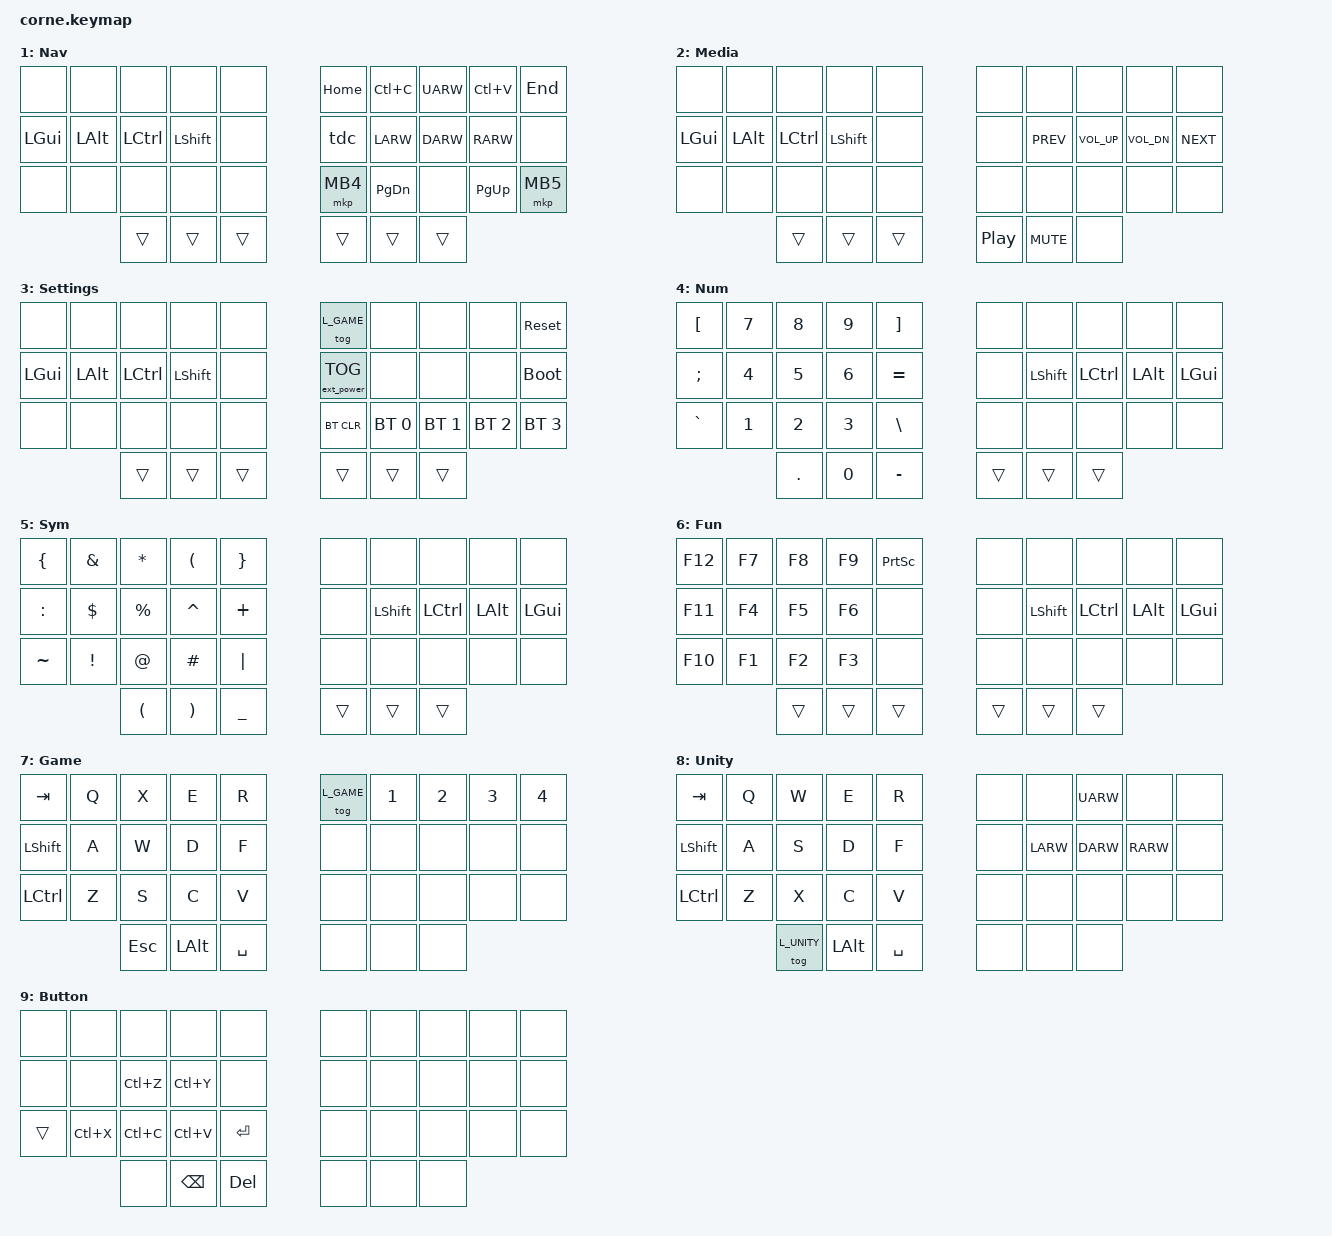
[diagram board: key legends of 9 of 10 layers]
// Copyright (c) 2022 The ZMK Contributors
// SPDX-License-Identifier: MIT

#include <behaviors.dtsi>
#include <dt-bindings/zmk/keys.h>
#include <dt-bindings/zmk/bt.h>
#include <dt-bindings/zmk/mouse.h>
#include <dt-bindings/zmk/ext_power.h>

// Layers
#define L_BASE      0
#define L_NAV       1
#define L_MEDIA     2
#define L_SETTINGS  3
#define L_NUM       4
#define L_SYM       5
#define L_FUN       6
#define L_GAME      7
#define L_UNITY     8
#define L_BUTTON    9

// Home rows
#define HRML(k1,k2,k3,k4) &pmt LGUI  k1  &mt LALT  k2   &mt LCTRL k3   &mt LSHFT k4
#define HRMR(k1,k2,k3,k4) &mt RSHFT k1   &mt RCTRL k2   &mt LALT  k3   &pmt RGUI k4

// Layer-taps
#define LT_MEDIA    &lt  L_MEDIA    TAB
#define LT_NAV      &lt  L_NAV      SPACE
#define LT_NUM      &lt  L_NUM      BSPC
#define LT_SYM      &lt  L_SYM      ENTER
#define LT_FUN      &lt  L_FUN      DEL
#define LT_BUT      &plt L_BUTTON   Z

// Layer-toggles
#define TOG_UNI     &tog L_UNITY
#define TOG_GAME    &tog L_GAME

// Other
#define POW_TOG &ext_power EP_TOG

&mt {
    flavor = "tap-preferred";
    tapping-term-ms = <200>;
    require-prior-idle-ms = <100>;
};

&lt {
    tapping-term-ms = <200>;
    quick-tap-ms = <150>;
};

/ {
    chosen {
      zmk,matrix_transform = &five_column_transform;
    };

    behaviors {
        pmt: pinkie_mod_tap {
            compatible = "zmk,behavior-hold-tap";
            #binding-cells = <2>;
            flavor = "tap-preferred";
            tapping-term-ms = <300>;
            require-prior-idle-ms = <150>;
            bindings = <&kp>, <&kp>;
        };

        plt: pinkie_layer_tap {
            compatible = "zmk,behavior-hold-tap";
            #binding-cells = <2>;
            flavor = "tap-preferred";
            tapping-term-ms = <250>;
            require-prior-idle-ms = <150>;
            bindings = <&mo>, <&kp>;
        };

        tdc: tap_dance_caps {
            compatible = "zmk,behavior-tap-dance";
            #binding-cells = <0>;
            tapping-term-ms = <200>;
            bindings = <&caps_word>, <&kp CAPS>;
        };
    };

    combos {
        compatible = "zmk,combos";

        combo_esc {
            timeout-ms = <50>;
            require-prior-idle-ms = <100>;
            key-positions = <0 1>;
            bindings = <&kp ESC>;
        };
    };

    conditional_layers {
        compatible = "zmk,conditional-layers";

        layer_tri_settings {
            if-layers = <L_NAV L_MEDIA>;
            then-layer = <L_SETTINGS>;
        };
    };

    keymap {
        compatible = "zmk,keymap";
        layer_base {
            display-name = "Base";
            bindings = <
        //╭──────────┬──────────┬──────────┬──────────┬──────────╮   ╭──────────┬──────────┬──────────┬──────────┬──────────╮
            &kp Q      &kp W      &kp E      &kp R      &kp T          &kp Y      &kp U      &kp I      &kp O      &kp P
        //├──────────┼──────────┼──────────┼──────────┼──────────┤   ├──────────┼──────────┼──────────┼──────────┼──────────┤
            HRML(A,        S,         D,         F)     &kp G          &kp H      HRMR(J,        K,         L,        SQT)
        //├──────────┼──────────┼──────────┼──────────┼──────────┤   ├──────────┼──────────┼──────────┼──────────┼──────────┤
            LT_BUT     &mt RALT X &kp C      &kp V      &kp B          &kp N      &kp M      &kp COMMA &mt RALT DOT &kp FSLH
        //╰──────────┴──────────┴──────────┼──────────┼──────────┤   ├──────────┼──────────┼──────────┴──────────┴──────────╯
                                  TOG_UNI    LT_MEDIA   LT_NAV         LT_SYM     LT_NUM     LT_FUN
        //                      ╰──────────┴──────────┴──────────╯   ╰──────────┴──────────┴──────────╯
            >;
        };

        layer_nav {
            display-name = "Nav";
            bindings = <
        //╭──────────┬──────────┬──────────┬──────────┬──────────╮   ╭──────────┬──────────┬──────────┬──────────┬──────────╮
            &none      &none      &none      &none      &none          &kp HOME   &kp LC(C)  &kp UARW   &kp LC(V)  &kp END
        //├──────────┼──────────┼──────────┼──────────┼──────────┤   ├──────────┼──────────┼──────────┼──────────┼──────────┤
            &kp LGUI   &kp LALT   &kp LCTRL  &kp LSHFT  &none          &tdc       &kp LARW   &kp DARW   &kp RARW   &none
        //├──────────┼──────────┼──────────┼──────────┼──────────┤   ├──────────┼──────────┼──────────┼──────────┼──────────┤
            &none      &none      &none      &none      &none          &mkp MB4   &kp PG_DN  &none      &kp PG_UP  &mkp MB5
        //╰──────────┴──────────┴──────────┼──────────┼──────────┤   ├──────────┼──────────┼──────────┴──────────┴──────────╯
                                  &trans     &trans     &trans         &trans     &trans     &trans
        //                      ╰──────────┴──────────┴──────────╯   ╰──────────┴──────────┴──────────╯
            >;
        };

        layer_media {
            display-name = "Media";
            bindings = <
        //╭──────────┬──────────┬──────────┬──────────┬──────────╮   ╭──────────┬──────────┬──────────┬──────────┬──────────╮
            &none      &none      &none      &none      &none          &none      &none      &none      &none      &none
        //├──────────┼──────────┼──────────┼──────────┼──────────┤   ├──────────┼──────────┼──────────┼──────────┼──────────┤
            &kp LGUI   &kp LALT   &kp LCTRL  &kp LSHFT  &none          &none    &kp C_PREV &kp C_VOL_UP &kp C_VOL_DN &kp C_NEXT
        //├──────────┼──────────┼──────────┼──────────┼──────────┤   ├──────────┼──────────┼──────────┼──────────┼──────────┤
            &none     &none       &none      &none      &none          &none      &none      &none      &none      &none
        //╰──────────┴──────────┴──────────┼──────────┼──────────┤   ├──────────┼──────────┼──────────┴──────────┴──────────╯
                                  &trans     &trans     &trans         &kp C_PP   &kp C_MUTE &none
        //                      ╰──────────┴──────────┴──────────╯   ╰──────────┴──────────┴──────────╯
            >;
        };

        layer_tri_settings {
            display-name = "Settings";
            bindings = <
        //╭──────────┬──────────┬──────────┬──────────┬──────────╮   ╭──────────┬──────────┬──────────┬──────────┬──────────╮
            &none      &none      &none      &none      &none         &tog L_GAME &none      &none      &none     &sys_reset
        //├──────────┼──────────┼──────────┼──────────┼──────────┤   ├──────────┼──────────┼──────────┼──────────┼──────────┤
            &kp LGUI   &kp LALT   &kp LCTRL  &kp LSHFT  &none          POW_TOG    &none      &none      &none     &bootloader
        //├──────────┼──────────┼──────────┼──────────┼──────────┤   ├──────────┼──────────┼──────────┼──────────┼──────────┤
            &none      &none      &none      &none      &none         &bt BT_CLR &bt BT_SEL 0 &bt BT_SEL 1 &bt BT_SEL 2 &bt BT_SEL 3 
        //╰──────────┴──────────┴──────────┼──────────┼──────────┤   ├──────────┼──────────┼──────────┴──────────┴──────────╯
                                  &trans     &trans     &trans         &trans     &trans     &trans
        //                      ╰──────────┴──────────┴──────────╯   ╰──────────┴──────────┴──────────╯
            >;
        };

        layer_numbers {
            display-name = "Num";
            bindings = <
        //╭──────────┬──────────┬──────────┬──────────┬──────────╮   ╭──────────┬──────────┬──────────┬──────────┬──────────╮
            &kp LBKT   &kp N7     &kp N8     &kp N9     &kp RBKT       &none      &none      &none      &none      &none
        //├──────────┼──────────┼──────────┼──────────┼──────────┤   ├──────────┼──────────┼──────────┼──────────┼──────────┤
            &kp SEMI   &kp N4     &kp N5     &kp N6     &kp EQUAL      &none      &kp LSHFT  &kp LCTRL  &kp LALT   &kp LGUI
        //├──────────┼──────────┼──────────┼──────────┼──────────┤   ├──────────┼──────────┼──────────┼──────────┼──────────┤
            &kp GRAVE  &kp N1     &kp N2     &kp N3     &kp BSLH       &none      &none      &none      &none      &none
        //╰──────────┴──────────┴──────────┼──────────┼──────────┤   ├──────────┼──────────┼──────────┴──────────┴──────────╯
                                  &kp DOT    &kp N0     &kp MINUS      &trans     &trans     &trans
        //                      ╰──────────┴──────────┴──────────╯   ╰──────────┴──────────┴──────────╯
            >;
        };

        layer_symbols {
            display-name = "Sym";
            bindings = <
        //╭──────────┬──────────┬──────────┬──────────┬──────────╮   ╭──────────┬──────────┬──────────┬──────────┬──────────╮
            &kp LBRC   &kp AMPS   &kp STAR   &kp LPAR   &kp RBRC       &none      &none      &none      &none      &none
        //├──────────┼──────────┼──────────┼──────────┼──────────┤   ├──────────┼──────────┼──────────┼──────────┼──────────┤
            &kp COLON  &kp DLLR   &kp PRCNT  &kp CARET  &kp PLUS       &none      &kp LSHFT  &kp LCTRL  &kp LALT   &kp LGUI
        //├──────────┼──────────┼──────────┼──────────┼──────────┤   ├──────────┼──────────┼──────────┼──────────┼──────────┤
            &kp TILDE  &kp EXCL   &kp AT     &kp POUND  &kp PIPE       &none      &none      &none      &none      &none
        //╰──────────┴──────────┴──────────┼──────────┼──────────┤   ├──────────┼──────────┼──────────┴──────────┴──────────╯
                                  &kp LPAR   &kp RPAR   &kp UNDER      &trans     &trans     &trans
        //                      ╰──────────┴──────────┴──────────╯   ╰──────────┴──────────┴──────────╯
            >;
        };

        layer_tri_function {
            display-name = "Fun";
            bindings = <
        //╭──────────┬──────────┬──────────┬──────────┬──────────╮   ╭──────────┬──────────┬──────────┬──────────┬──────────╮
            &kp F12    &kp F7     &kp F8     &kp F9     &kp PSCRN      &none      &none      &none      &none      &none
        //├──────────┼──────────┼──────────┼──────────┼──────────┤   ├──────────┼──────────┼──────────┼──────────┼──────────┤
            &kp F11    &kp F4     &kp F5     &kp F6     &none          &none      &kp LSHFT  &kp LCTRL  &kp LALT   &kp LGUI
        //├──────────┼──────────┼──────────┼──────────┼──────────┤   ├──────────┼──────────┼──────────┼──────────┼──────────┤
            &kp F10    &kp F1     &kp F2     &kp F3     &none          &none      &none      &none      &none      &none
        //╰──────────┴──────────┴──────────┼──────────┼──────────┤   ├──────────┼──────────┼──────────┴──────────┴──────────╯
                                  &trans     &trans     &trans         &trans     &trans     &trans
        //                      ╰──────────┴──────────┴──────────╯   ╰──────────┴──────────┴──────────╯
            >;
        };

        layer_game {
        display-name = "Game";
            bindings = <
        //╭──────────┬──────────┬──────────┬──────────┬──────────╮   ╭──────────┬──────────┬──────────┬──────────┬──────────╮
            &kp TAB    &kp Q      &kp X      &kp E      &kp R         &tog L_GAME &kp 1     &kp 2      &kp 3      &kp 4
        //├──────────┼──────────┼──────────┼──────────┼──────────┤   ├──────────┼──────────┼──────────┼──────────┼──────────┤
            &kp LSHFT  &kp A      &kp W      &kp D      &kp F          &none      &none      &none      &none      &none
        //├──────────┼──────────┼──────────┼──────────┼──────────┤   ├──────────┼──────────┼──────────┼──────────┼──────────┤
            &kp LCTRL  &kp Z      &kp S      &kp C      &kp V          &none      &none      &none      &none      &none
        //╰──────────┴──────────┴──────────┼──────────┼──────────┤   ├──────────┼──────────┼──────────┴──────────┴──────────╯
                                  &kp ESC    &kp LALT   &kp SPACE      &none      &none      &none
        //                      ╰──────────┴──────────┴──────────╯   ╰──────────┴──────────┴──────────╯
            >;
        };

        layer_unity {
            display-name = "Unity";
            bindings = <
        //╭──────────┬──────────┬──────────┬──────────┬──────────╮   ╭──────────┬──────────┬──────────┬──────────┬──────────╮
            &kp TAB    &kp Q      &kp W      &kp E      &kp R          &none      &none      &kp UARW   &none      &none
        //├──────────┼──────────┼──────────┼──────────┼──────────┤   ├──────────┼──────────┼──────────┼──────────┼──────────┤
            &kp LSHFT  &kp A      &kp S      &kp D      &kp F          &none      &kp LARW   &kp DARW   &kp RARW   &none
        //├──────────┼──────────┼──────────┼──────────┼──────────┤   ├──────────┼──────────┼──────────┼──────────┼──────────┤
            &kp LCTRL  &kp Z      &kp X      &kp C      &kp V          &none      &none      &none      &none      &none
        //╰──────────┴──────────┴──────────┼──────────┼──────────┤   ├──────────┼──────────┼──────────┴──────────┴──────────╯
                                  TOG_UNI    &kp LALT   &kp SPACE      &none      &none      &none
        //                      ╰──────────┴──────────┴──────────╯   ╰──────────┴──────────┴──────────╯
            >;
        };

        layer_button {
            display-name = "Button";
            bindings = <
        //╭──────────┬──────────┬──────────┬──────────┬──────────╮   ╭──────────┬──────────┬──────────┬──────────┬──────────╮
            &none      &none      &none      &none      &none          &none      &none      &none      &none      &none
        //├──────────┼──────────┼──────────┼──────────┼──────────┤   ├──────────┼──────────┼──────────┼──────────┼──────────┤
            &none      &none      &kp LC(Z)  &kp LC(Y)  &none          &none      &none      &none      &none      &none
        //├──────────┼──────────┼──────────┼──────────┼──────────┤   ├──────────┼──────────┼──────────┼──────────┼──────────┤
            &trans     &kp LC(X)  &kp LC(C)  &kp LC(V)  &kp ENTER      &none      &none      &none      &none      &none
        //╰──────────┴──────────┴──────────┼──────────┼──────────┤   ├──────────┼──────────┼──────────┴──────────┴──────────╯
                                  &none      &kp BSPC   &kp DEL        &none      &none      &none
        //                      ╰──────────┴──────────┴──────────╯   ╰──────────┴──────────┴──────────╯
            >;
        };
    };
};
